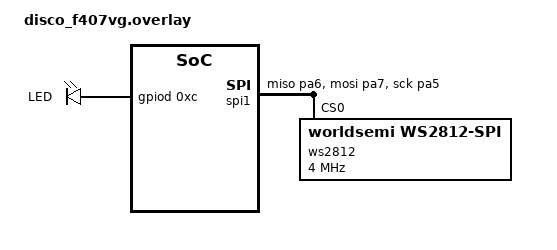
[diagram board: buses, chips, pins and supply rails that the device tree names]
#include <zephyr/dt-bindings/gpio/gpio.h>
#include <zephyr/dt-bindings/led/led.h>
#include <zephyr/dt-bindings/pinctrl/stm32-pinctrl-common.h>

&spi1 {
    pinctrl-0 = <&spi1_miso_pa6 &spi1_mosi_pa7 &spi1_sck_pa5>;
    pinctrl-names = "default";
    status = "okay";
    
	ws2812: ws2812@0 {
		compatible = "worldsemi,ws2812-spi";

		/* SPI */
		reg = <0>; /* ignored, but necessary for SPI bindings */
		spi-max-frequency = <4000000>;
		frame-format = <32768>; /* SPI_FRAME_FORMAT_TI */

		/* WS2812 */
		chain-length = <12>; /* arbitrary; change at will */
		spi-one-frame = <0x70>; 
		spi-zero-frame = <0x40>;
		color-mapping = <LED_COLOR_ID_GREEN
				 LED_COLOR_ID_RED
				 LED_COLOR_ID_BLUE>;
	};
};

&spi1_miso_pa6 {
    slew-rate = "very-high-speed";
};

&spi1_mosi_pa7 {
    slew-rate = "very-high-speed";
};

/ {
    leds {
		compatible = "gpio-leds";
		led0: led0 {
			gpios = < &gpiod 0xc 0x0 >;
			label = "LED";
		};
	};
    aliases {
        led0 = &led0;
        led-strip = &ws2812;
    };
};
